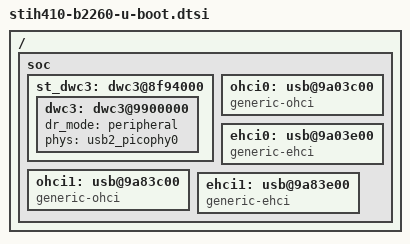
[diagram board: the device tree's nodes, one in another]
// SPDX-License-Identifier: GPL-2.0
/*
 * Copyright (C) 2018, STMicroelectronics - All Rights Reserved
 * Author(s): Patrice Chotard, <patrice.chotard@foss.st.com> for STMicroelectronics.
 *
 */

/{
	soc {
		st_dwc3: dwc3@8f94000 {
			dwc3: dwc3@9900000 {
				dr_mode	= "peripheral";
				phys = <&usb2_picophy0>;
			};
		};

		ohci0: usb@9a03c00 {
			compatible = "generic-ohci";
		};

		ehci0: usb@9a03e00 {
			compatible = "generic-ehci";
		};

		ohci1: usb@9a83c00 {
			compatible = "generic-ohci";
		};

		ehci1: usb@9a83e00 {
			compatible = "generic-ehci";
		};
	};
};
